# MU3E_HISTOGRAM_INGRESS_BRIDGE register map
Vendor: Mu3e; Series: MU3E_FPGA_IP; File version: 26.0.9.0515
CMSIS-SVD description of the histogram ingress selector bridge CSR aperture. BaseAddress is 0 because this file describes the relative CSR aperture of the IP; system integration supplies the live slave base address.
Registers are 32-bit, read-only, reset 0x0 unless marked. A register's access mark holds for its fields unless they carry their own. Offsets are from the block's base; lines under a group give offsets from that group; [hi:lo] are bit positions; {n}, {i} and the like mark numbered series; 'fields as' and 'values as' point back to an identical list; <NAME> marks a mode.

## Memory map
0x00000000 HISTOGRAM_INGRESS_BRIDGE_CSR size 0x20 — Relative 8-word CSR aperture for the histogram ingress selector bridge.

## HISTOGRAM_INGRESS_BRIDGE_CSR — Relative 8-word CSR aperture for the histogram ingress selector bridge.
Base 0x00000000
0x00 UID reset 0x48495342 — Software-visible IP identifier. Default ASCII "HISB" (0x48495342).
  [31:0] value — Compile-time or integration-time UID word. Default ASCII "HISB".
0x04 META rw — Read-multiplexed metadata word. Write meta_sel[1:0] before reading back: 0=VERSION, 1=DATE, 2=GIT, 3=INSTANCE_ID.
  [1:0] meta_sel — Selects the META read page.
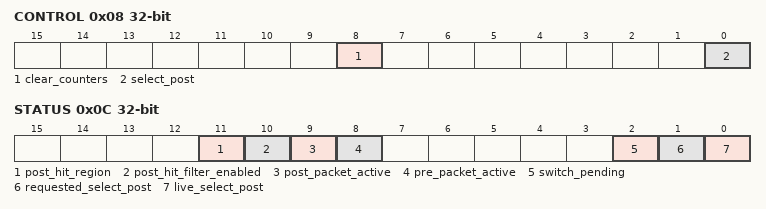
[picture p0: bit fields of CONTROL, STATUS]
0x08 CONTROL rw — Requested histogram source and counter clear control. The bridge applies a source change once both input streams are beat-idle and the post-hit-stack frame is idle.
  [8] clear_counters wo — Write 1 to clear PRE_SEEN_COUNT, POST_SEEN_COUNT, HIST_EMIT_COUNT, and HIST_DROP_COUNT.
  [0] select_post — 0 selects pre-hit-stack traffic, 1 selects post-hit-stack traffic.
0x0C STATUS — Live selector state and idle visibility for source switching. The pre packet-active field is run-level status and does not block source switching.
  [11] post_hit_region — Current post-stream parser state. 1 after a K23.7 subheader until the next frame header or trailer.
  [10] post_hit_filter_enabled — 1 when the post-hit-stack histogram tap forwards only real hit words after K23.7 subheaders.
  [9] post_packet_active — 1 while the forwarded post-hit-stack path is inside a packet. This blocks source switching.
  [8] pre_packet_active — 1 while the forwarded pre-hit-stack path is inside a run-level packet. This is status-only for source switching.
  [2] switch_pending — 1 while the requested source differs from the live source.
  [1] requested_select_post — Last requested histogram source from CONTROL.select_post.
  [0] live_select_post — Currently active histogram source. 0=pre, 1=post.
0x10 PRE_SEEN_COUNT — Saturating count of pre_in accepted beats since reset or CONTROL.clear_counters.
  [31:0] value — Pre-rbCAM accepted beat count.
0x14 POST_SEEN_COUNT — Saturating count of accepted post_in hit words after the optional post hit filter since reset or CONTROL.clear_counters.
  [31:0] value — Post-rbCAM accepted hit-word count.
0x18 HIST_EMIT_COUNT — Saturating count of histogram output handshakes since reset or CONTROL.clear_counters.
  [31:0] value — Histogram output handshake count.
0x1C HIST_DROP_COUNT — Saturating count of selected histogram valid cycles stalled by hist_out.ready low since reset or CONTROL.clear_counters.
  [31:0] value — Selected histogram stall count.
